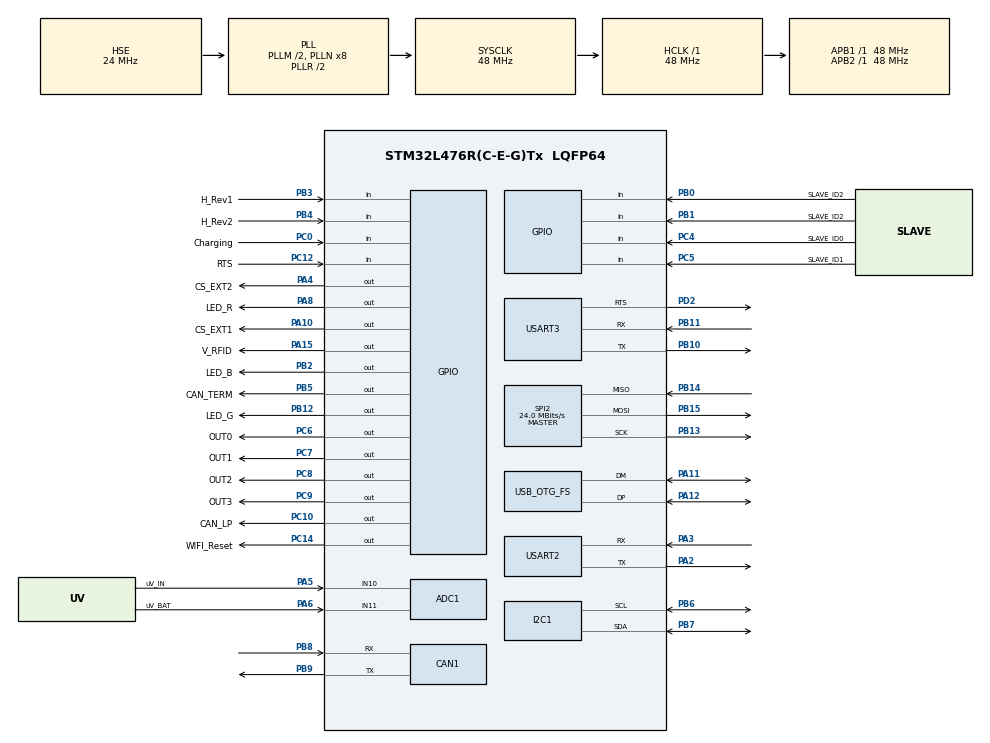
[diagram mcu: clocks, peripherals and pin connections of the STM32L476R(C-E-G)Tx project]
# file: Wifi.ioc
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ADC1.Channel-10\#ChannelRegularConversion=ADC_CHANNEL_10
ADC1.NbrOfConversionFlag=1
ADC1.OffsetNumber-10\#ChannelRegularConversion=ADC_OFFSET_NONE
ADC1.Rank-10\#ChannelRegularConversion=1
ADC1.SamplingTime-10\#ChannelRegularConversion=ADC_SAMPLETIME_2CYCLES_5
ADC1.master=1
CAN1.CalculateTimeQuantum=333.3333333333333
Dma.Request0=USART2_RX
Dma.Request1=USART2_TX
Dma.Request2=USART3_RX
Dma.Request3=USART3_TX
Dma.USART2_RX.0.Direction=DMA_PERIPH_TO_MEMORY
Dma.USART2_RX.0.Instance=DMA1_Channel6
Dma.USART2_RX.0.MemDataAlignment=DMA_MDATAALIGN_BYTE
Dma.USART2_RX.0.MemInc=DMA_MINC_ENABLE
Dma.USART2_RX.0.Mode=DMA_NORMAL
Dma.USART2_RX.0.PeriphDataAlignment=DMA_PDATAALIGN_BYTE
Dma.USART2_RX.0.PeriphInc=DMA_PINC_DISABLE
Dma.USART2_RX.0.Priority=DMA_PRIORITY_MEDIUM
Dma.USART2_TX.1.Direction=DMA_MEMORY_TO_PERIPH
Dma.USART2_TX.1.Instance=DMA1_Channel7
Dma.USART2_TX.1.MemDataAlignment=DMA_MDATAALIGN_BYTE
Dma.USART2_TX.1.MemInc=DMA_MINC_ENABLE
Dma.USART2_TX.1.Mode=DMA_NORMAL
Dma.USART2_TX.1.PeriphDataAlignment=DMA_PDATAALIGN_BYTE
Dma.USART2_TX.1.PeriphInc=DMA_PINC_DISABLE
Dma.USART2_TX.1.Priority=DMA_PRIORITY_MEDIUM
Dma.USART3_RX.2.Direction=DMA_PERIPH_TO_MEMORY
Dma.USART3_RX.2.Instance=DMA1_Channel3
Dma.USART3_RX.2.MemDataAlignment=DMA_MDATAALIGN_BYTE
Dma.USART3_RX.2.MemInc=DMA_MINC_ENABLE
Dma.USART3_RX.2.Mode=DMA_NORMAL
Dma.USART3_RX.2.PeriphDataAlignment=DMA_PDATAALIGN_BYTE
Dma.USART3_RX.2.PeriphInc=DMA_PINC_DISABLE
Dma.USART3_RX.2.Priority=DMA_PRIORITY_LOW
Dma.USART3_TX.3.Direction=DMA_MEMORY_TO_PERIPH
Dma.USART3_TX.3.Instance=DMA1_Channel2
Dma.USART3_TX.3.MemDataAlignment=DMA_MDATAALIGN_BYTE
Dma.USART3_TX.3.MemInc=DMA_MINC_ENABLE
Dma.USART3_TX.3.Mode=DMA_NORMAL
Dma.USART3_TX.3.PeriphDataAlignment=DMA_PDATAALIGN_BYTE
Dma.USART3_TX.3.PeriphInc=DMA_PINC_DISABLE
Dma.USART3_TX.3.Priority=DMA_PRIORITY_LOW
I2C1.Timing=0x20303E5D
Mcu.Family=STM32L4
Mcu.Name=STM32L476R(C-E-G)Tx
Mcu.Package=LQFP64
NVIC.DMA1_Channel2_IRQn=true\:0\:0\:false\:false\:true\:false
NVIC.DMA1_Channel3_IRQn=true\:0\:0\:false\:false\:true\:false
NVIC.DMA1_Channel6_IRQn=true\:0\:0\:false\:false\:true\:false
NVIC.DMA1_Channel7_IRQn=true\:0\:0\:false\:false\:true\:false
NVIC.OTG_FS_IRQn=true\:0\:0\:false\:false\:true\:false
NVIC.PriorityGroup=NVIC_PRIORITYGROUP_4
PA10.GPIO_Label=CS_EXT1
PA10.Signal=GPIO_Output
PA11.Mode=Device_Only
PA11.Signal=USB_OTG_FS_DM
PA12.Mode=Device_Only
PA12.Signal=USB_OTG_FS_DP
PA15\ (JTDI).GPIO_Label=V_RFID
PA15\ (JTDI).Signal=GPIO_Output
PA2.Mode=Asynchronous
PA2.Signal=USART2_TX
PA3.Mode=Asynchronous
PA3.Signal=USART2_RX
PA4.GPIO_Label=CS_EXT2
PA4.Signal=GPIO_Output
PA5.GPIO_Label=uV_IN
PA5.Signal=ADCx_IN10
PA6.GPIO_Label=uV_BAT
PA6.Signal=ADCx_IN11
PA8.GPIO_Label=LED_R
PA8.Signal=GPIO_Output
PB0.GPIO_Label=SLAVE_ID2
PB0.Signal=GPIO_Input
PB1.GPIO_Label=SLAVE_ID2
PB1.Signal=GPIO_Input
PB10.Mode=Asynchronous
PB10.Signal=USART3_TX
PB11.Mode=Asynchronous
PB11.Signal=USART3_RX
PB12.GPIO_Label=LED_G
PB12.Signal=GPIO_Output
PB13.Mode=Full_Duplex_Master
PB13.Signal=SPI2_SCK
PB14.Mode=Full_Duplex_Master
PB14.Signal=SPI2_MISO
PB15.Mode=Full_Duplex_Master
PB15.Signal=SPI2_MOSI
PB2.GPIO_Label=LED_B
PB2.Signal=GPIO_Output
PB3\ (JTDO-TRACESWO).GPIO_Label=H_Rev1
PB3\ (JTDO-TRACESWO).Signal=GPIO_Input
PB4\ (NJTRST).GPIO_Label=H_Rev2
PB4\ (NJTRST).Signal=GPIO_Input
PB5.GPIO_Label=CAN_TERM
PB5.Signal=GPIO_Output
PB6.Mode=I2C
PB6.Signal=I2C1_SCL
PB7.Mode=I2C
PB7.Signal=I2C1_SDA
PB8.Mode=Master
PB8.Signal=CAN1_RX
PB9.Mode=Master
PB9.Signal=CAN1_TX
PC0.GPIO_Label=Charging
PC0.Signal=GPIO_Input
PC10.GPIO_Label=CAN_LP
PC10.Signal=GPIO_Output
PC12.GPIO_Label=RTS
PC12.Signal=GPIO_Input
PC14-OSC32_IN\ (PC14).GPIO_Label=WIFI_Reset
PC14-OSC32_IN\ (PC14).Signal=GPIO_Output
PC4.GPIO_Label=SLAVE_ID0
PC4.Signal=GPIO_Input
PC5.GPIO_Label=SLAVE_ID1
PC5.Signal=GPIO_Input
PC6.GPIO_Label=OUT0
PC6.Signal=GPIO_Output
PC7.GPIO_Label=OUT1
PC7.Signal=GPIO_Output
PC8.GPIO_Label=OUT2
PC8.Signal=GPIO_Output
PC9.GPIO_Label=OUT3
PC9.Signal=GPIO_Output
PD2.Mode=RTS_Only
PD2.Signal=USART3_RTS
PH0-OSC_IN\ (PH0).Mode=HSE-External-Oscillator
PH0-OSC_IN\ (PH0).Signal=RCC_OSC_IN
PH1-OSC_OUT\ (PH1).Mode=HSE-External-Oscillator
PH1-OSC_OUT\ (PH1).Signal=RCC_OSC_OUT
ProjectManager.HeapSize=0x200
ProjectManager.StackSize=0x400
ProjectManager.TargetToolchain=TrueSTUDIO
RCC.ADCFreq_Value=48000000
RCC.AHBFreq_Value=48000000
RCC.APB1Freq_Value=48000000
RCC.APB1TimFreq_Value=48000000
RCC.APB2Freq_Value=48000000
RCC.APB2TimFreq_Value=48000000
RCC.CortexFreq_Value=48000000
RCC.HCLKFreq_Value=48000000
RCC.HSE_VALUE=24000000
RCC.HSI_VALUE=16000000
RCC.LSE_VALUE=32768
RCC.MSI_VALUE=4000000
RCC.PLLM=2
RCC.PLLSAI1N=16
RCC.PLLSAI1Q=RCC_PLLQ_DIV4
RCC.PLLSAI1R=RCC_PLLR_DIV4
RCC.PLLSourceVirtual=RCC_PLLSOURCE_HSE
RCC.SYSCLKFreq_VALUE=48000000
RCC.SYSCLKSource=RCC_SYSCLKSOURCE_PLLCLK
RCC.USBFreq_Value=48000000
RCC.VCOOutputFreq_Value=96000000
SH.ADCx_IN10.0=ADC1_IN10,IN10-Single-Ended
SH.ADCx_IN11.0=ADC1_IN11,IN11-Single-Ended
SPI2.BaudRatePrescaler=SPI_BAUDRATEPRESCALER_2
SPI2.CalculateBaudRate=24.0 MBits/s
SPI2.Direction=SPI_DIRECTION_2LINES
SPI2.Mode=SPI_MODE_MASTER
SPI2.VirtualType=VM_MASTER
USART2.VirtualMode-Asynchronous=VM_ASYNC
USART3.VirtualMode-Asynchronous=VM_ASYNC
USB_DEVICE.CLASS_NAME_FS=CDC
USB_DEVICE.VirtualMode=Cdc
USB_DEVICE.VirtualModeFS=Cdc_FS
USB_OTG_FS.VirtualMode=Device_Only
VP_IWDG_VS_IWDG.Mode=IWDG_Activate
VP_USB_DEVICE_VS_USB_DEVICE_CDC_FS.Mode=CDC_FS
board=custom

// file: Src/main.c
/**
  ******************************************************************************
  * @file           : main.c
  * @brief          : Main program body
  ******************************************************************************
  * This notice applies to any and all portions of this file
  * that are not between comment pairs USER CODE BEGIN and
  * USER CODE END. Other portions of this file, whether
  * inserted by the user or by software development tools
  * are owned by their respective copyright owners.
  *
  * Copyright (c) 2018 STMicroelectronics International N.V.
  * All rights reserved.
  *
  * Redistribution and use in source and binary forms, with or without
  * modification, are permitted, provided that the following conditions are met:
  *
  * 1. Redistribution of source code must retain the above copyright notice,
  *    this list of conditions and the following disclaimer.
  * 2. Redistributions in binary form must reproduce the above copyright notice,
  *    this list of conditions and the following disclaimer in the documentation
  *    and/or other materials provided with the distribution.
  * 3. Neither the name of STMicroelectronics nor the names of other
  *    contributors to this software may be used to endorse or promote products
  *    derived from this software without specific written permission.
  * 4. This software, including modifications and/or derivative works of this
  *    software, must execute solely and exclusively on microcontroller or
  *    microprocessor devices manufactured by or for STMicroelectronics.
  * 5. Redistribution and use of this software other than as permitted under
  *    this license is void and will automatically terminate your rights under
  *    this license.
  *
  * THIS SOFTWARE IS PROVIDED BY STMICROELECTRONICS AND CONTRIBUTORS "AS IS"
  * AND ANY EXPRESS, IMPLIED OR STATUTORY WARRANTIES, INCLUDING, BUT NOT
  * LIMITED TO, THE IMPLIED WARRANTIES OF MERCHANTABILITY, FITNESS FOR A
  * PARTICULAR PURPOSE AND NON-INFRINGEMENT OF THIRD PARTY INTELLECTUAL PROPERTY
  * RIGHTS ARE DISCLAIMED TO THE FULLEST EXTENT PERMITTED BY LAW. IN NO EVENT
  * SHALL STMICROELECTRONICS OR CONTRIBUTORS BE LIABLE FOR ANY DIRECT, INDIRECT,
  * INCIDENTAL, SPECIAL, EXEMPLARY, OR CONSEQUENTIAL DAMAGES (INCLUDING, BUT NOT
  * LIMITED TO, PROCUREMENT OF SUBSTITUTE GOODS OR SERVICES; LOSS OF USE, DATA,
  * OR PROFITS; OR BUSINESS INTERRUPTION) HOWEVER CAUSED AND ON ANY THEORY OF
  * LIABILITY, WHETHER IN CONTRACT, STRICT LIABILITY, OR TORT (INCLUDING
  * NEGLIGENCE OR OTHERWISE) ARISING IN ANY WAY OUT OF THE USE OF THIS SOFTWARE,
  * EVEN IF ADVISED OF THE POSSIBILITY OF SUCH DAMAGE.
  *
  ******************************************************************************
  */
#include "main.h"
#include "stm32l4xx_hal.h"
#include "adc.h"
#include "can.h"
#include "dma.h"
#include "i2c.h"
#include "iwdg.h"
#include "spi.h"
#include "usart.h"
#include "usb_device.h"
#include "gpio.h"

/* USER CODE BEGIN PV */
/* Private variables ---------------------------------------------------------*/

/* USER CODE END PV */

void SystemClock_Config(void);

/* USER CODE BEGIN PFP */
/* Private function prototypes -----------------------------------------------*/

/* USER CODE END PFP */

/* USER CODE BEGIN 0 */
__IO ITStatus UartReady = RESET;

/* Buffer used for transmission */

#define RXBUFFERSIZE 256
#define TXBUFFERSIZE 17
/* Buffer used for reception */
uint8_t aRxBuffer[RXBUFFERSIZE];
uint8_t aTxBuffer[] = "+++\r\nAT+GMI\r\n";
uint8_t UID_bytes[8];

/* USER CODE END 0 */

int main(void)
{

  /* MCU Configuration----------------------------------------------------------*/

  /* Reset of all peripherals, Initializes the Flash interface and the Systick. */
  HAL_Init();

  /* Configure the system clock */
  SystemClock_Config();

  /* Initialize all configured peripherals */
  MX_GPIO_Init();
  MX_DMA_Init();
  MX_USART2_UART_Init();
  MX_CAN1_Init();
  MX_I2C1_Init();
  MX_SPI2_Init();
  MX_ADC1_Init();
  MX_USART3_UART_Init();
 // MX_IWDG_Init();
  MX_USB_DEVICE_Init();
  /* USER CODE BEGIN 2 */

  HAL_GPIO_WritePin(  V_RFID_GPIO_Port,V_RFID_Pin,GPIO_PIN_SET);
  HAL_GPIO_WritePin(LED_R_GPIO_Port,LED_R_Pin,GPIO_PIN_SET);
  HAL_GPIO_WritePin(LED_G_GPIO_Port,LED_G_Pin,GPIO_PIN_SET);
  HAL_GPIO_WritePin(LED_B_GPIO_Port,LED_B_Pin,GPIO_PIN_SET);
  /* USER CODE END 2 */
  if(HAL_UART_Receive_DMA(&huart2, (uint8_t *)aRxBuffer, RXBUFFERSIZE) != HAL_OK)
   {
     Error_Handler();
   }

   /*##-3- Start the transmission process #####################################*/
   /* While the UART in reception process, user can transmit data through
      "aTxBuffer" buffer */
   if(HAL_UART_Transmit_DMA(&huart2, (uint8_t*)aTxBuffer, TXBUFFERSIZE)!= HAL_OK)
   {
     Error_Handler();
   }

   RFID_Read_UID(UID_bytes);

  /* Infinite loop */
  /* USER CODE BEGIN WHILE */
  while (1)
  {
	  RFID_Read_UID(UID_bytes);
	  HAL_Delay(5000);

  /* USER CODE END WHILE */

  }

}

void SystemClock_Config(void)
{

  RCC_OscInitTypeDef RCC_OscInitStruct;
  RCC_ClkInitTypeDef RCC_ClkInitStruct;
  RCC_PeriphCLKInitTypeDef PeriphClkInit;

    /**Initializes the CPU, AHB and APB busses clocks
    */
  RCC_OscInitStruct.OscillatorType = RCC_OSCILLATORTYPE_LSI|RCC_OSCILLATORTYPE_HSE;
  RCC_OscInitStruct.HSEState = RCC_HSE_ON;
  RCC_OscInitStruct.LSIState = RCC_LSI_ON;
  RCC_OscInitStruct.PLL.PLLState = RCC_PLL_ON;
  RCC_OscInitStruct.PLL.PLLSource = RCC_PLLSOURCE_HSE;
  RCC_OscInitStruct.PLL.PLLM = 2;
  RCC_OscInitStruct.PLL.PLLN = 8;
  RCC_OscInitStruct.PLL.PLLP = RCC_PLLP_DIV7;
  RCC_OscInitStruct.PLL.PLLQ = RCC_PLLQ_DIV2;
  RCC_OscInitStruct.PLL.PLLR = RCC_PLLR_DIV2;
  if (HAL_RCC_OscConfig(&RCC_OscInitStruct) != HAL_OK)
  {
    _Error_Handler(__FILE__, __LINE__);
  }

    /**Initializes the CPU, AHB and APB busses clocks
    */
  RCC_ClkInitStruct.ClockType = RCC_CLOCKTYPE_HCLK|RCC_CLOCKTYPE_SYSCLK
                              |RCC_CLOCKTYPE_PCLK1|RCC_CLOCKTYPE_PCLK2;
  RCC_ClkInitStruct.SYSCLKSource = RCC_SYSCLKSOURCE_PLLCLK;
  RCC_ClkInitStruct.AHBCLKDivider = RCC_SYSCLK_DIV1;
  RCC_ClkInitStruct.APB1CLKDivider = RCC_HCLK_DIV1;
  RCC_ClkInitStruct.APB2CLKDivider = RCC_HCLK_DIV1;

  if (HAL_RCC_ClockConfig(&RCC_ClkInitStruct, FLASH_LATENCY_2) != HAL_OK)
  {
    _Error_Handler(__FILE__, __LINE__);
  }

  PeriphClkInit.PeriphClockSelection = RCC_PERIPHCLK_USART2|RCC_PERIPHCLK_USART3
                              |RCC_PERIPHCLK_I2C1|RCC_PERIPHCLK_USB
                              |RCC_PERIPHCLK_ADC;
  PeriphClkInit.Usart2ClockSelection = RCC_USART2CLKSOURCE_PCLK1;
  PeriphClkInit.Usart3ClockSelection = RCC_USART3CLKSOURCE_PCLK1;
  PeriphClkInit.I2c1ClockSelection = RCC_I2C1CLKSOURCE_PCLK1;
  PeriphClkInit.AdcClockSelection = RCC_ADCCLKSOURCE_PLLSAI1;
  PeriphClkInit.UsbClockSelection = RCC_USBCLKSOURCE_PLLSAI1;
  PeriphClkInit.PLLSAI1.PLLSAI1Source = RCC_PLLSOURCE_HSE;
  PeriphClkInit.PLLSAI1.PLLSAI1M = 2;
  PeriphClkInit.PLLSAI1.PLLSAI1N = 16;
  PeriphClkInit.PLLSAI1.PLLSAI1P = RCC_PLLP_DIV7;
  PeriphClkInit.PLLSAI1.PLLSAI1Q = RCC_PLLQ_DIV4;
  PeriphClkInit.PLLSAI1.PLLSAI1R = RCC_PLLR_DIV4;
  PeriphClkInit.PLLSAI1.PLLSAI1ClockOut = RCC_PLLSAI1_48M2CLK|RCC_PLLSAI1_ADC1CLK;
  if (HAL_RCCEx_PeriphCLKConfig(&PeriphClkInit) != HAL_OK)
  {
    _Error_Handler(__FILE__, __LINE__);
  }

    /**Configure the main internal regulator output voltage
    */
  if (HAL_PWREx_ControlVoltageScaling(PWR_REGULATOR_VOLTAGE_SCALE1) != HAL_OK)
  {
    _Error_Handler(__FILE__, __LINE__);
  }

    /**Configure the Systick interrupt time
    */
  HAL_SYSTICK_Config(HAL_RCC_GetHCLKFreq()/1000);

    /**Configure the Systick
    */
  HAL_SYSTICK_CLKSourceConfig(SYSTICK_CLKSOURCE_HCLK);

  /* SysTick_IRQn interrupt configuration */
  HAL_NVIC_SetPriority(SysTick_IRQn, 0, 0);
}

void _Error_Handler(char *file, int line)
{
  while(1)
  {
  }
}

/************************ (C) COPYRIGHT STMicroelectronics *****END OF FILE****/
